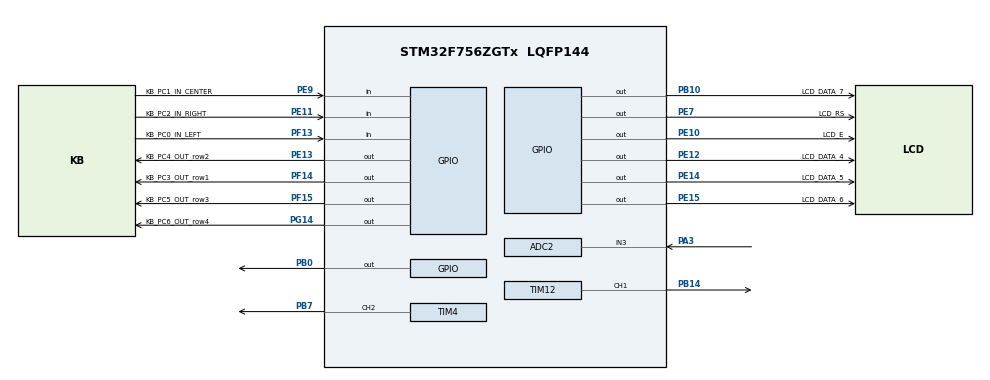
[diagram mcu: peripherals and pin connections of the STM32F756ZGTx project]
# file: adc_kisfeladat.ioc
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ADC1.Channel-0\#ChannelRegularConversion=ADC_CHANNEL_TEMPSENSOR
ADC1.NbrOfConversionFlag=1
ADC1.Rank-0\#ChannelRegularConversion=1
ADC1.SamplingTime-0\#ChannelRegularConversion=ADC_SAMPLETIME_3CYCLES
ADC1.master=1
ADC2.Channel-0\#ChannelRegularConversion=ADC_CHANNEL_3
ADC2.NbrOfConversionFlag=1
ADC2.Rank-0\#ChannelRegularConversion=1
ADC2.SamplingTime-0\#ChannelRegularConversion=ADC_SAMPLETIME_3CYCLES
Mcu.Family=STM32F7
Mcu.Name=STM32F756ZGTx
Mcu.Package=LQFP144
NVIC.PriorityGroup=NVIC_PRIORITYGROUP_4
NVIC.TIM4_IRQn=true\:0\:0\:false\:false\:true\:true\:true
NVIC.TIM8_BRK_TIM12_IRQn=true\:0\:0\:false\:false\:true\:true\:true
PA3.Signal=ADCx_IN3
PB0.Signal=GPIO_Output
PB10.GPIO_Label=LCD_DATA_7
PB10.Signal=GPIO_Output
PB14.Signal=S_TIM12_CH1
PB7.Signal=S_TIM4_CH2
PE10.GPIO_Label=LCD_E
PE10.Signal=GPIO_Output
PE11.GPIO_Label=KB_PC2_IN_RIGHT
PE11.Signal=GPIO_Input
PE12.GPIO_Label=LCD_DATA_4
PE12.Signal=GPIO_Output
PE13.GPIO_Label=KB_PC4_OUT_row2
PE13.Signal=GPIO_Output
PE14.GPIO_Label=LCD_DATA_5
PE14.Signal=GPIO_Output
PE15.GPIO_Label=LCD_DATA_6
PE15.Signal=GPIO_Output
PE7.GPIO_Label=LCD_RS
PE7.Signal=GPIO_Output
PE9.GPIO_Label=KB_PC1_IN_CENTER
PE9.Signal=GPIO_Input
PF13.GPIO_Label=KB_PC0_IN_LEFT
PF13.Signal=GPIO_Input
PF14.GPIO_Label=KB_PC3_OUT_row1
PF14.Signal=GPIO_Output
PF15.GPIO_Label=KB_PC5_OUT_row3
PF15.Signal=GPIO_Output
PG14.GPIO_Label=KB_PC6_OUT_row4
PG14.Signal=GPIO_Output
ProjectManager.HeapSize=0x200
ProjectManager.StackSize=0x400
ProjectManager.TargetToolchain=TrueSTUDIO
RCC.HSE_VALUE=25000000
RCC.HSI_VALUE=16000000
RCC.LSE_VALUE=32768
RCC.USBFreq_Value=96000000
RCC.VCOOutputFreq_Value=192000000
SH.ADCx_IN3.0=ADC2_IN3,IN3
SH.S_TIM12_CH1.0=TIM12_CH1,PWM Generation1 CH1
SH.S_TIM4_CH2.0=TIM4_CH2,PWM Generation2 CH2
TIM12.Channel-PWM\ Generation1\ CH1=TIM_CHANNEL_1
TIM12.Period=100
TIM12.Prescaler=15
TIM12.Pulse-PWM\ Generation1\ CH1=5
TIM4.Channel-PWM\ Generation2\ CH2=TIM_CHANNEL_2
TIM4.Period=100
TIM4.Prescaler=15
TIM4.Pulse-PWM\ Generation2\ CH2=5
VP_ADC1_TempSens_Input.Mode=IN-TempSens
board=custom

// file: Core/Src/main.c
/* USER CODE BEGIN Header */
/**
  ******************************************************************************
  * @file           : main.c
  * @brief          : Main program body
  ******************************************************************************
  * @attention
  *
  * <h2><center>&copy; Copyright (c) 2021 STMicroelectronics.
  * All rights reserved.</center></h2>
  *
  * This software component is licensed by ST under BSD 3-Clause license,
  * the "License"; You may not use this file except in compliance with the
  * License. You may obtain a copy of the License at:
  *                        opensource.org/licenses/BSD-3-Clause
  *
  ******************************************************************************
  */
/* USER CODE END Header */
#include "main.h"

/* USER CODE BEGIN Includes */
#include "lcd.h"
#include "matrix.h"
/* USER CODE END Includes */

ADC_HandleTypeDef hadc1;
ADC_HandleTypeDef hadc2;

TIM_HandleTypeDef htim4;
TIM_HandleTypeDef htim12;

uint32_t adc_data_reg;
uint32_t v_adc_ch3 = 0;
uint16_t cnt=0;

void SystemClock_Config(void);
static void MX_GPIO_Init(void);
static void MX_TIM4_Init(void);
static void MX_TIM12_Init(void);
static void MX_ADC1_Init(void);
static void MX_ADC2_Init(void);
/* USER CODE BEGIN PFP */
void HAL_TIM_PeriodElapsedCallback (TIM_HandleTypeDef * htim){
	if(cnt==2000){
		HAL_ADC_Start(&hadc2); //adc conv start
		//HAL_Delay(50);
		adc_data_reg = HAL_ADC_GetValue(&hadc2);
		v_adc_ch3 = (3300*adc_data_reg)/4096;

		cnt=0;
	}
	cnt++;

}
/* USER CODE END PFP */

int main(void)
{

  /* MCU Configuration--------------------------------------------------------*/

  /* Reset of all peripherals, Initializes the Flash interface and the Systick. */
  HAL_Init();

  /* Configure the system clock */
  SystemClock_Config();

  /* Initialize all configured peripherals */
  MX_GPIO_Init();
  MX_TIM4_Init();
  MX_TIM12_Init();
  MX_ADC1_Init();
  MX_ADC2_Init();
  /* USER CODE BEGIN 2 */
  HAL_TIM_Base_Start_IT(&htim4);
  LCD_init();
  LCD_cmd(0x80);

  /* USER CODE END 2 */

  /* Infinite loop */
  while (1)
  {

	  LCD_xy(0,1);
	  if(v_adc_ch3>=3000)
	  	  	  {

	  	  		  LCD_xy(9,4); LCD_string("XXXXX");
	  	  	  }

	  if((v_adc_ch3>=2001) && (v_adc_ch3<=3000))
	  	  {
		  LCD_xy(9,4); LCD_string("XXXX ");
	  	  }

	  	  if((v_adc_ch3>=1001) && (v_adc_ch3<=2000))
	  	  {
	  		LCD_xy(9,4); LCD_string("XXX  ");
	  	  	}

	  	  	if((v_adc_ch3<=1000) && (v_adc_ch3>=501))
	  	  	 {
	  	  		LCD_xy(9,4); LCD_string("XX    ");
	  	 }

	  	  if(v_adc_ch3<500)
	  	  {

	  		  LCD_xy(9,4);; LCD_string("X     ");
	  	  }
  }
}

void SystemClock_Config(void)
{
  RCC_OscInitTypeDef RCC_OscInitStruct = {0};
  RCC_ClkInitTypeDef RCC_ClkInitStruct = {0};

  /** Configure the main internal regulator output voltage
  */
  __HAL_RCC_PWR_CLK_ENABLE();
  __HAL_PWR_VOLTAGESCALING_CONFIG(PWR_REGULATOR_VOLTAGE_SCALE3);
  /** Initializes the RCC Oscillators according to the specified parameters
  * in the RCC_OscInitTypeDef structure.
  */
  RCC_OscInitStruct.OscillatorType = RCC_OSCILLATORTYPE_HSI;
  RCC_OscInitStruct.HSIState = RCC_HSI_ON;
  RCC_OscInitStruct.HSICalibrationValue = RCC_HSICALIBRATION_DEFAULT;
  RCC_OscInitStruct.PLL.PLLState = RCC_PLL_NONE;
  if (HAL_RCC_OscConfig(&RCC_OscInitStruct) != HAL_OK)
  {
    Error_Handler();
  }
  /** Initializes the CPU, AHB and APB buses clocks
  */
  RCC_ClkInitStruct.ClockType = RCC_CLOCKTYPE_HCLK|RCC_CLOCKTYPE_SYSCLK
                              |RCC_CLOCKTYPE_PCLK1|RCC_CLOCKTYPE_PCLK2;
  RCC_ClkInitStruct.SYSCLKSource = RCC_SYSCLKSOURCE_HSI;
  RCC_ClkInitStruct.AHBCLKDivider = RCC_SYSCLK_DIV1;
  RCC_ClkInitStruct.APB1CLKDivider = RCC_HCLK_DIV1;
  RCC_ClkInitStruct.APB2CLKDivider = RCC_HCLK_DIV1;

  if (HAL_RCC_ClockConfig(&RCC_ClkInitStruct, FLASH_LATENCY_0) != HAL_OK)
  {
    Error_Handler();
  }
}

static void MX_ADC1_Init(void)
{

  ADC_ChannelConfTypeDef sConfig = {0};

  /** Configure the global features of the ADC (Clock, Resolution, Data Alignment and number of conversion)
  */
  hadc1.Instance = ADC1;
  hadc1.Init.ClockPrescaler = ADC_CLOCK_SYNC_PCLK_DIV2;
  hadc1.Init.Resolution = ADC_RESOLUTION_12B;
  hadc1.Init.ScanConvMode = ADC_SCAN_DISABLE;
  hadc1.Init.ContinuousConvMode = DISABLE;
  hadc1.Init.DiscontinuousConvMode = DISABLE;
  hadc1.Init.ExternalTrigConvEdge = ADC_EXTERNALTRIGCONVEDGE_NONE;
  hadc1.Init.ExternalTrigConv = ADC_SOFTWARE_START;
  hadc1.Init.DataAlign = ADC_DATAALIGN_RIGHT;
  hadc1.Init.NbrOfConversion = 1;
  hadc1.Init.DMAContinuousRequests = DISABLE;
  hadc1.Init.EOCSelection = ADC_EOC_SINGLE_CONV;
  if (HAL_ADC_Init(&hadc1) != HAL_OK)
  {
    Error_Handler();
  }
  /** Configure for the selected ADC regular channel its corresponding rank in the sequencer and its sample time.
  */
  sConfig.Channel = ADC_CHANNEL_TEMPSENSOR;
  sConfig.Rank = ADC_REGULAR_RANK_1;
  sConfig.SamplingTime = ADC_SAMPLETIME_3CYCLES;
  if (HAL_ADC_ConfigChannel(&hadc1, &sConfig) != HAL_OK)
  {
    Error_Handler();
  }

}

static void MX_ADC2_Init(void)
{

  ADC_ChannelConfTypeDef sConfig = {0};

  /** Configure the global features of the ADC (Clock, Resolution, Data Alignment and number of conversion)
  */
  hadc2.Instance = ADC2;
  hadc2.Init.ClockPrescaler = ADC_CLOCK_SYNC_PCLK_DIV2;
  hadc2.Init.Resolution = ADC_RESOLUTION_12B;
  hadc2.Init.ScanConvMode = ADC_SCAN_DISABLE;
  hadc2.Init.ContinuousConvMode = DISABLE;
  hadc2.Init.DiscontinuousConvMode = DISABLE;
  hadc2.Init.ExternalTrigConvEdge = ADC_EXTERNALTRIGCONVEDGE_NONE;
  hadc2.Init.ExternalTrigConv = ADC_SOFTWARE_START;
  hadc2.Init.DataAlign = ADC_DATAALIGN_RIGHT;
  hadc2.Init.NbrOfConversion = 1;
  hadc2.Init.DMAContinuousRequests = DISABLE;
  hadc2.Init.EOCSelection = ADC_EOC_SINGLE_CONV;
  if (HAL_ADC_Init(&hadc2) != HAL_OK)
  {
    Error_Handler();
  }
  /** Configure for the selected ADC regular channel its corresponding rank in the sequencer and its sample time.
  */
  sConfig.Channel = ADC_CHANNEL_3;
  sConfig.Rank = ADC_REGULAR_RANK_1;
  sConfig.SamplingTime = ADC_SAMPLETIME_3CYCLES;
  if (HAL_ADC_ConfigChannel(&hadc2, &sConfig) != HAL_OK)
  {
    Error_Handler();
  }

}

static void MX_TIM4_Init(void)
{

  TIM_MasterConfigTypeDef sMasterConfig = {0};
  TIM_OC_InitTypeDef sConfigOC = {0};

  htim4.Instance = TIM4;
  htim4.Init.Prescaler = 15;
  htim4.Init.CounterMode = TIM_COUNTERMODE_UP;
  htim4.Init.Period = 100;
  htim4.Init.ClockDivision = TIM_CLOCKDIVISION_DIV1;
  htim4.Init.AutoReloadPreload = TIM_AUTORELOAD_PRELOAD_DISABLE;
  if (HAL_TIM_PWM_Init(&htim4) != HAL_OK)
  {
    Error_Handler();
  }
  sMasterConfig.MasterOutputTrigger = TIM_TRGO_RESET;
  sMasterConfig.MasterSlaveMode = TIM_MASTERSLAVEMODE_DISABLE;
  if (HAL_TIMEx_MasterConfigSynchronization(&htim4, &sMasterConfig) != HAL_OK)
  {
    Error_Handler();
  }
  sConfigOC.OCMode = TIM_OCMODE_PWM1;
  sConfigOC.Pulse = 5;
  sConfigOC.OCPolarity = TIM_OCPOLARITY_HIGH;
  sConfigOC.OCFastMode = TIM_OCFAST_DISABLE;
  if (HAL_TIM_PWM_ConfigChannel(&htim4, &sConfigOC, TIM_CHANNEL_2) != HAL_OK)
  {
    Error_Handler();
  }
  HAL_TIM_MspPostInit(&htim4);

}

static void MX_TIM12_Init(void)
{

  TIM_OC_InitTypeDef sConfigOC = {0};

  htim12.Instance = TIM12;
  htim12.Init.Prescaler = 15;
  htim12.Init.CounterMode = TIM_COUNTERMODE_UP;
  htim12.Init.Period = 100;
  htim12.Init.ClockDivision = TIM_CLOCKDIVISION_DIV1;
  htim12.Init.AutoReloadPreload = TIM_AUTORELOAD_PRELOAD_DISABLE;
  if (HAL_TIM_PWM_Init(&htim12) != HAL_OK)
  {
    Error_Handler();
  }
  sConfigOC.OCMode = TIM_OCMODE_PWM1;
  sConfigOC.Pulse = 5;
  sConfigOC.OCPolarity = TIM_OCPOLARITY_HIGH;
  sConfigOC.OCFastMode = TIM_OCFAST_DISABLE;
  if (HAL_TIM_PWM_ConfigChannel(&htim12, &sConfigOC, TIM_CHANNEL_1) != HAL_OK)
  {
    Error_Handler();
  }
  HAL_TIM_MspPostInit(&htim12);

}

static void MX_GPIO_Init(void)
{
  GPIO_InitTypeDef GPIO_InitStruct = {0};

  /* GPIO Ports Clock Enable */
  __HAL_RCC_GPIOA_CLK_ENABLE();
  __HAL_RCC_GPIOB_CLK_ENABLE();
  __HAL_RCC_GPIOF_CLK_ENABLE();
  __HAL_RCC_GPIOE_CLK_ENABLE();
  __HAL_RCC_GPIOG_CLK_ENABLE();

  /*Configure GPIO pin Output Level */
  HAL_GPIO_WritePin(GPIOB, GPIO_PIN_0|LCD_DATA_7_Pin, GPIO_PIN_RESET);

  /*Configure GPIO pin Output Level */
  HAL_GPIO_WritePin(GPIOF, KB_PC3_OUT_row1_Pin|KB_PC5_OUT_row3_Pin, GPIO_PIN_RESET);

  /*Configure GPIO pin Output Level */
  HAL_GPIO_WritePin(GPIOE, LCD_RS_Pin|LCD_E_Pin|LCD_DATA_4_Pin|KB_PC4_OUT_row2_Pin
                          |LCD_DATA_5_Pin|LCD_DATA_6_Pin, GPIO_PIN_RESET);

  /*Configure GPIO pin Output Level */
  HAL_GPIO_WritePin(KB_PC6_OUT_row4_GPIO_Port, KB_PC6_OUT_row4_Pin, GPIO_PIN_RESET);

  /*Configure GPIO pins : PB0 LCD_DATA_7_Pin */
  GPIO_InitStruct.Pin = GPIO_PIN_0|LCD_DATA_7_Pin;
  GPIO_InitStruct.Mode = GPIO_MODE_OUTPUT_PP;
  GPIO_InitStruct.Pull = GPIO_NOPULL;
  GPIO_InitStruct.Speed = GPIO_SPEED_FREQ_LOW;
  HAL_GPIO_Init(GPIOB, &GPIO_InitStruct);

  /*Configure GPIO pin : KB_PC0_IN_LEFT_Pin */
  GPIO_InitStruct.Pin = KB_PC0_IN_LEFT_Pin;
  GPIO_InitStruct.Mode = GPIO_MODE_INPUT;
  GPIO_InitStruct.Pull = GPIO_NOPULL;
  HAL_GPIO_Init(KB_PC0_IN_LEFT_GPIO_Port, &GPIO_InitStruct);

  /*Configure GPIO pins : KB_PC3_OUT_row1_Pin KB_PC5_OUT_row3_Pin */
  GPIO_InitStruct.Pin = KB_PC3_OUT_row1_Pin|KB_PC5_OUT_row3_Pin;
  GPIO_InitStruct.Mode = GPIO_MODE_OUTPUT_PP;
  GPIO_InitStruct.Pull = GPIO_NOPULL;
  GPIO_InitStruct.Speed = GPIO_SPEED_FREQ_LOW;
  HAL_GPIO_Init(GPIOF, &GPIO_InitStruct);

  /*Configure GPIO pins : LCD_RS_Pin LCD_E_Pin LCD_DATA_4_Pin KB_PC4_OUT_row2_Pin
                           LCD_DATA_5_Pin LCD_DATA_6_Pin */
  GPIO_InitStruct.Pin = LCD_RS_Pin|LCD_E_Pin|LCD_DATA_4_Pin|KB_PC4_OUT_row2_Pin
                          |LCD_DATA_5_Pin|LCD_DATA_6_Pin;
  GPIO_InitStruct.Mode = GPIO_MODE_OUTPUT_PP;
  GPIO_InitStruct.Pull = GPIO_NOPULL;
  GPIO_InitStruct.Speed = GPIO_SPEED_FREQ_LOW;
  HAL_GPIO_Init(GPIOE, &GPIO_InitStruct);

  /*Configure GPIO pins : KB_PC1_IN_CENTER_Pin KB_PC2_IN_RIGHT_Pin */
  GPIO_InitStruct.Pin = KB_PC1_IN_CENTER_Pin|KB_PC2_IN_RIGHT_Pin;
  GPIO_InitStruct.Mode = GPIO_MODE_INPUT;
  GPIO_InitStruct.Pull = GPIO_NOPULL;
  HAL_GPIO_Init(GPIOE, &GPIO_InitStruct);

  /*Configure GPIO pin : KB_PC6_OUT_row4_Pin */
  GPIO_InitStruct.Pin = KB_PC6_OUT_row4_Pin;
  GPIO_InitStruct.Mode = GPIO_MODE_OUTPUT_PP;
  GPIO_InitStruct.Pull = GPIO_NOPULL;
  GPIO_InitStruct.Speed = GPIO_SPEED_FREQ_LOW;
  HAL_GPIO_Init(KB_PC6_OUT_row4_GPIO_Port, &GPIO_InitStruct);

}

void Error_Handler(void)
{
  __disable_irq();
  while (1)
  {
  }
}

/************************ (C) COPYRIGHT STMicroelectronics *****END OF FILE****/
